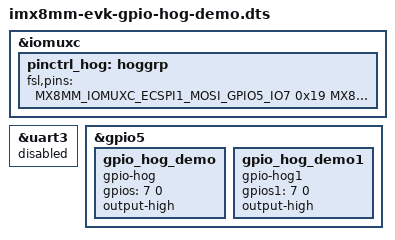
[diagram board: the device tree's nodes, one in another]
// SPDX-License-Identifier: (GPL-2.0+ OR MIT)
/*
 * Copyright 2019-2020 NXP
 */

/dts-v1/;


#include "imx8mm-evk.dts"

&iomuxc {

    /delete-node/ pinctrl_uart3; 
         
    pinctrl_hog: hoggrp {
        fsl,pins = < 
            MX8MM_IOMUXC_ECSPI1_MOSI_GPIO5_IO7 0x19
            MX8MM_IOMUXC_ECSPI1_MISO_GPIO5_IO8 0x19
            >;
    };
};

&uart3 {
    status = "disabled";
};


&gpio5 {

    gpio_hog_demo {
        gpio-hog;
        gpios = <7 0>;
       /* output-low;*/
        output-high;
     };

    gpio_hog_demo1 {
        gpio-hog1;
        gpios1 = <7 0>;
       /* output-low;*/
        output-high;
     };

};
